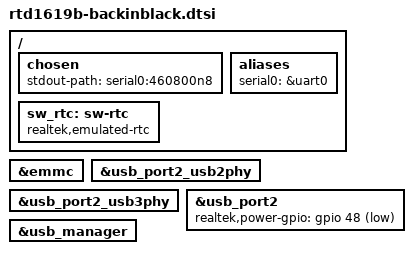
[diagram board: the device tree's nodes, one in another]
// SPDX-License-Identifier: (GPL-2.0-or-later OR BSD-2-Clause)
/*
 * Copyright (c) 2021 Realtek Semiconductor Corp.
 */

/dts-v1/;

#include "rtd16xxb.dtsi"

/ {
	chosen {
		stdout-path = "serial0:460800n8";
	};

	aliases {
		serial0 = &uart0;
	};

	sw_rtc: sw-rtc {
		compatible = "realtek,emulated-rtc";
	};
};

&emmc {
	status = "okay";
};

&usb_port2_usb2phy {
	status = "okay";
};

&usb_port2_usb3phy {
	status = "okay";
};

&usb_port2 {
	status = "okay";
	realtek,power-gpio = <&gpio 48 GPIO_ACTIVE_LOW>;
	//dwc3@50000 {
	//	role-switch-default-mode = "host"; /* host, peripheral*/
	//};
};

&usb_manager {
	status = "okay";
};

/delete-node/ &type_c;
